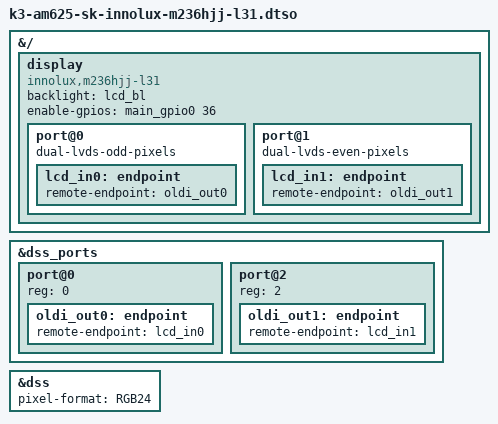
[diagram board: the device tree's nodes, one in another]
// SPDX-License-Identifier: GPL-2.0
/*
 * AM625 SK: INNOLUX - at070tn92 RGB LCD panel
 *
 * Copyright (C) 2021-2022 Texas Instruments Incorporated - https://www.ti.com/
 */

/dts-v1/;
/plugin/;

#include <dt-bindings/gpio/gpio.h>
#include <dt-bindings/interrupt-controller/irq.h>
#include "k3-pinctrl.h"

&{/} {
	display {
        compatible = "innolux,m236hjj-l31";
		backlight = <&lcd_bl>;
		enable-gpios = <&main_gpio0 36 GPIO_ACTIVE_HIGH>;

        /*
        * Note that the OLDI TX 0 transmits the odd set of pixels
        * while the OLDI TX 1 transmits the even set. This is a
        * fixed configuration in the IP integration and is not
        * changeable. The properties, "dual-lvds-odd-pixels" and
        * "dual-lvds-even-pixels" have been used to merely
        * identify if a Dual Link configuration is required.
        * Swapping them will not make any difference.
        */
        port@0 {
            dual-lvds-odd-pixels;
            lcd_in0: endpoint {
                remote-endpoint = <&oldi_out0>;
            };
        };

        port@1 {
            dual-lvds-even-pixels;
            lcd_in1: endpoint {
                remote-endpoint = <&oldi_out1>;
            };
		};
	};
};


&dss_ports {
    #address-cells = <1>;
    #size-cells = <0>;

    /* VP1: LVDS Output (OLDI TX 0) */
    port@0 {
            reg = <0>;
            oldi_out0: endpoint {
                    remote-endpoint = <&lcd_in0>;
            };
    };

    /* VP1: LVDS Output (OLDI TX 1) */
    port@2 {
            reg = <2>;
            oldi_out1: endpoint {
                    remote-endpoint = <&lcd_in1>;
            };
    };
};

&dss {
        pixel-format = "RGB24";
};
